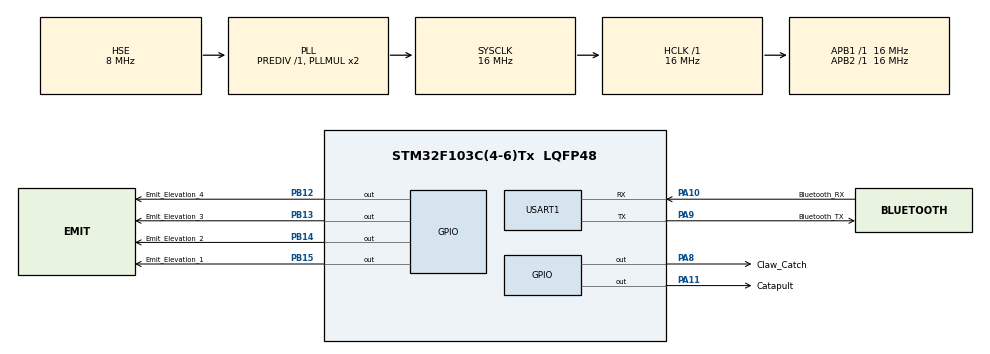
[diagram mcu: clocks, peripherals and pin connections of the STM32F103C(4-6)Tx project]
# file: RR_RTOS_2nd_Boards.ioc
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FREERTOS.BinarySemaphores01=Claw_Catch_BinarySem,Dynamic,NULL;Catapult_BinarySem,Dynamic,NULL;Emit_Elevation_BinarySem,Dynamic,NULL
FREERTOS.INCLUDE_vTaskDelayUntil=1
FREERTOS.Tasks01=BLUETOOTH,0,128,bluetooth_task,As weak,NULL,Dynamic,NULL,NULL;CLAW_CATCH,0,128,claw_catch_task,As weak,NULL,Dynamic,NULL,NULL;CATAPULT,0,128,catapult_task,As weak,NULL,Dynamic,NULL,NULL;EMIT_ELEVATION,0,128,emit_elevation_task,As weak,NULL,Dynamic,NULL,NULL
Mcu.Family=STM32F1
Mcu.Name=STM32F103C(4-6)Tx
Mcu.Package=LQFP48
NVIC.PriorityGroup=NVIC_PRIORITYGROUP_4
NVIC.TIM3_IRQn=true\:15\:0\:false\:false\:true\:false\:false\:true\:true
NVIC.TimeBase=TIM3_IRQn
NVIC.TimeBaseIP=TIM3
PA10.GPIO_Label=Bluetooth_RX
PA10.Mode=Asynchronous
PA10.Signal=USART1_RX
PA11.GPIO_Label=Catapult
PA11.Signal=GPIO_Output
PA13.Mode=Serial_Wire
PA13.Signal=SYS_JTMS-SWDIO
PA14.Mode=Serial_Wire
PA14.Signal=SYS_JTCK-SWCLK
PA8.GPIO_Label=Claw_Catch
PA8.Signal=GPIO_Output
PA9.GPIO_Label=Bluetooth_TX
PA9.Mode=Asynchronous
PA9.Signal=USART1_TX
PB12.GPIO_Label=Emit_Elevation_4
PB12.Signal=GPIO_Output
PB13.GPIO_Label=Emit_Elevation_3
PB13.Signal=GPIO_Output
PB14.GPIO_Label=Emit_Elevation_2
PB14.Signal=GPIO_Output
PB15.GPIO_Label=Emit_Elevation_1
PB15.Signal=GPIO_Output
PD0-OSC_IN.Mode=HSE-External-Oscillator
PD0-OSC_IN.Signal=RCC_OSC_IN
PD1-OSC_OUT.Mode=HSE-External-Oscillator
PD1-OSC_OUT.Signal=RCC_OSC_OUT
ProjectManager.HeapSize=0x200
ProjectManager.StackSize=0x400
ProjectManager.TargetToolchain=MDK-ARM V5.32
RCC.AHBFreq_Value=16000000
RCC.APB1Freq_Value=16000000
RCC.APB1TimFreq_Value=16000000
RCC.APB2Freq_Value=16000000
RCC.APB2TimFreq_Value=16000000
RCC.HCLKFreq_Value=16000000
RCC.PLLSourceVirtual=RCC_PLLSOURCE_HSE
RCC.SYSCLKFreq_VALUE=16000000
RCC.SYSCLKSource=RCC_SYSCLKSOURCE_PLLCLK
RCC.USBFreq_Value=16000000
USART1.VirtualMode=VM_ASYNC
VP_FREERTOS_VS_CMSIS_V1.Mode=CMSIS_V1
VP_SYS_VS_tim3.Mode=TIM3
board=custom

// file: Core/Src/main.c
/* USER CODE BEGIN Header */
/**
  ******************************************************************************
  * @file           : main.c
  * @brief          : Main program body
  ******************************************************************************
  * @attention
  *
  * Copyright (c) 2023 STMicroelectronics.
  * All rights reserved.
  *
  * This software is licensed under terms that can be found in the LICENSE file
  * in the root directory of this software component.
  * If no LICENSE file comes with this software, it is provided AS-IS.
  *
  ******************************************************************************
  */
/* USER CODE END Header */
#include "main.h"
#include "cmsis_os.h"
#include "usart.h"
#include "gpio.h"

void SystemClock_Config(void);
void MX_FREERTOS_Init(void);

/* USER CODE BEGIN 0 */
//extern uint8_t bluetooth_rx_buffer[1];
/* USER CODE END 0 */

int main(void)
{

  /* MCU Configuration--------------------------------------------------------*/

  /* Reset of all peripherals, Initializes the Flash interface and the Systick. */
  HAL_Init();

  /* Configure the system clock */
  SystemClock_Config();

  /* Initialize all configured peripherals */
  MX_GPIO_Init();
  MX_USART1_UART_Init();
  /* USER CODE BEGIN 2 */
//	HAL_UART_Receive_IT(&huart1,bluetooth_rx_buffer,1);
  /* USER CODE END 2 */

  /* Call init function for freertos objects (in freertos.c) */
  MX_FREERTOS_Init();

  /* Start scheduler */
  osKernelStart();

  /* We should never get here as control is now taken by the scheduler */
  /* Infinite loop */
  while (1)
  {

  }
}

void SystemClock_Config(void)
{
  RCC_OscInitTypeDef RCC_OscInitStruct = {0};
  RCC_ClkInitTypeDef RCC_ClkInitStruct = {0};

  /** Initializes the RCC Oscillators according to the specified parameters
  * in the RCC_OscInitTypeDef structure.
  */
  RCC_OscInitStruct.OscillatorType = RCC_OSCILLATORTYPE_HSE;
  RCC_OscInitStruct.HSEState = RCC_HSE_ON;
  RCC_OscInitStruct.HSEPredivValue = RCC_HSE_PREDIV_DIV1;
  RCC_OscInitStruct.HSIState = RCC_HSI_ON;
  RCC_OscInitStruct.PLL.PLLState = RCC_PLL_ON;
  RCC_OscInitStruct.PLL.PLLSource = RCC_PLLSOURCE_HSE;
  RCC_OscInitStruct.PLL.PLLMUL = RCC_PLL_MUL2;
  if (HAL_RCC_OscConfig(&RCC_OscInitStruct) != HAL_OK)
  {
    Error_Handler();
  }

  /** Initializes the CPU, AHB and APB buses clocks
  */
  RCC_ClkInitStruct.ClockType = RCC_CLOCKTYPE_HCLK|RCC_CLOCKTYPE_SYSCLK
                              |RCC_CLOCKTYPE_PCLK1|RCC_CLOCKTYPE_PCLK2;
  RCC_ClkInitStruct.SYSCLKSource = RCC_SYSCLKSOURCE_PLLCLK;
  RCC_ClkInitStruct.AHBCLKDivider = RCC_SYSCLK_DIV1;
  RCC_ClkInitStruct.APB1CLKDivider = RCC_HCLK_DIV1;
  RCC_ClkInitStruct.APB2CLKDivider = RCC_HCLK_DIV1;

  if (HAL_RCC_ClockConfig(&RCC_ClkInitStruct, FLASH_LATENCY_0) != HAL_OK)
  {
    Error_Handler();
  }
}

void HAL_TIM_PeriodElapsedCallback(TIM_HandleTypeDef *htim)
{
  if (htim->Instance == TIM3) {
    HAL_IncTick();
  }
}

void Error_Handler(void)
{
  __disable_irq();
  while (1)
  {
  }
}

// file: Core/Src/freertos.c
/* USER CODE BEGIN Header */
/**
  ******************************************************************************
  * File Name          : freertos.c
  * Description        : Code for freertos applications
  ******************************************************************************
  * @attention
  *
  * Copyright (c) 2023 STMicroelectronics.
  * All rights reserved.
  *
  * This software is licensed under terms that can be found in the LICENSE file
  * in the root directory of this software component.
  * If no LICENSE file comes with this software, it is provided AS-IS.
  *
  ******************************************************************************
  */
/* USER CODE END Header */

#include "FreeRTOS.h"
#include "task.h"
#include "main.h"
#include "cmsis_os.h"

osThreadId BLUETOOTHHandle;
osThreadId CLAW_CATCHHandle;
osThreadId CATAPULTHandle;
osThreadId EMIT_ELEVATIONHandle;
osSemaphoreId Claw_Catch_BinarySemHandle;
osSemaphoreId Catapult_BinarySemHandle;
osSemaphoreId Emit_Elevation_BinarySemHandle;

void bluetooth_task(void const * argument);
void claw_catch_task(void const * argument);
void catapult_task(void const * argument);
void emit_elevation_task(void const * argument);

void MX_FREERTOS_Init(void); /* (MISRA C 2004 rule 8.1) */

/* GetIdleTaskMemory prototype (linked to static allocation support) */
void vApplicationGetIdleTaskMemory( StaticTask_t **ppxIdleTaskTCBBuffer, StackType_t **ppxIdleTaskStackBuffer, uint32_t *pulIdleTaskStackSize );

/* USER CODE BEGIN GET_IDLE_TASK_MEMORY */
static StaticTask_t xIdleTaskTCBBuffer;
static StackType_t xIdleStack[configMINIMAL_STACK_SIZE];

void vApplicationGetIdleTaskMemory( StaticTask_t **ppxIdleTaskTCBBuffer, StackType_t **ppxIdleTaskStackBuffer, uint32_t *pulIdleTaskStackSize )
{
  *ppxIdleTaskTCBBuffer = &xIdleTaskTCBBuffer;
  *ppxIdleTaskStackBuffer = &xIdleStack[0];
  *pulIdleTaskStackSize = configMINIMAL_STACK_SIZE;
  /* place for user code */
}
/* USER CODE END GET_IDLE_TASK_MEMORY */

void MX_FREERTOS_Init(void) {

  /* Create the semaphores(s) */
  /* definition and creation of Claw_Catch_BinarySem */
  osSemaphoreDef(Claw_Catch_BinarySem);
  Claw_Catch_BinarySemHandle = osSemaphoreCreate(osSemaphore(Claw_Catch_BinarySem), 1);

  /* definition and creation of Catapult_BinarySem */
  osSemaphoreDef(Catapult_BinarySem);
  Catapult_BinarySemHandle = osSemaphoreCreate(osSemaphore(Catapult_BinarySem), 1);

  /* definition and creation of Emit_Elevation_BinarySem */
  osSemaphoreDef(Emit_Elevation_BinarySem);
  Emit_Elevation_BinarySemHandle = osSemaphoreCreate(osSemaphore(Emit_Elevation_BinarySem), 1);

  /* Create the thread(s) */
  /* definition and creation of BLUETOOTH */
  osThreadDef(BLUETOOTH, bluetooth_task, osPriorityNormal, 0, 128);
  BLUETOOTHHandle = osThreadCreate(osThread(BLUETOOTH), NULL);

  /* definition and creation of CLAW_CATCH */
  osThreadDef(CLAW_CATCH, claw_catch_task, osPriorityNormal, 0, 128);
  CLAW_CATCHHandle = osThreadCreate(osThread(CLAW_CATCH), NULL);

  /* definition and creation of CATAPULT */
  osThreadDef(CATAPULT, catapult_task, osPriorityNormal, 0, 128);
  CATAPULTHandle = osThreadCreate(osThread(CATAPULT), NULL);

  /* definition and creation of EMIT_ELEVATION */
  osThreadDef(EMIT_ELEVATION, emit_elevation_task, osPriorityNormal, 0, 128);
  EMIT_ELEVATIONHandle = osThreadCreate(osThread(EMIT_ELEVATION), NULL);

}

__weak void bluetooth_task(void const * argument)
{
  for(;;)
  {
    osDelay(1);
  }
}

__weak void claw_catch_task(void const * argument)
{
  for(;;)
  {
    osDelay(1);
  }
}

__weak void catapult_task(void const * argument)
{
  for(;;)
  {
    osDelay(1);
  }
}

__weak void emit_elevation_task(void const * argument)
{
  for(;;)
  {
    osDelay(1);
  }
}
